# ATA8515 device description
Architecture: AVR8; Family: megaAVR
Registers are 8-bit, access not given, no defined reset value unless marked. A register's access mark holds for its fields unless they carry their own. Offsets are from the block's base; [hi:lo] are bit positions; {n}, {i} and the like mark numbered series.

## FUSE
Instances: FUSE 0 in fuses
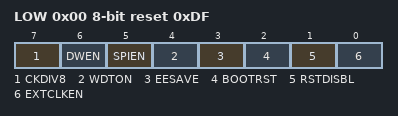
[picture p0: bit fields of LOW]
0x00 LOW reset 0xDF
  [7] CKDIV8 — Divide clock by 8 internally
  [6] DWEN — Debug Wire enable
  [5] SPIEN — Serial program downloading (SPI) enabled
  [4] WDTON — Watch-dog Timer always on
  [3] EESAVE — Preserve EEPROM memory through the Chip Erase cycle
  [2] BOOTRST — Select interrupt vector location
  [1] RSTDISBL — Disable external Reset
  [0] EXTCLKEN — External Clock enable

## LOCKBIT
Instances: LOCKBIT 0 in lockbits
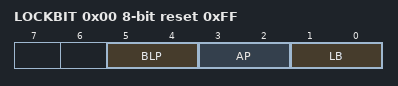
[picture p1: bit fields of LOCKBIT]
0x00 LOCKBIT reset 0xFF
  [5:4] BLP — Boot Loader Protection
    0=LPM_AND_SPM_PROHIBITED_IN_BOOT_LOADER_SECTION; 16=LPM_PROHIBITED_IN_BOOT_LOADER_SECTION; 32=SPM_PROHIBITED_IN_BOOT_LOADER_SECTION; 48=NO_LOCK_ON_SPM_AND_LPM_IN_BOOT_LOADER_SECTION
  [3:2] AP — Application Protection
    0=LPM_AND_SPM_PROHIBITED_IN_APPLICATION_SECTION; 4=LPM_PROHIBITED_IN_APPLICATION_SECTION; 8=SPM_PROHIBITED_IN_APPLICATION_SECTION; 12=NO_LOCK_ON_SPM_AND_LPM_IN_APPLICATION_SECTION
  [1:0] LB — Memory Lock
    0=PROG_VER_DISABLED (Further programming and verification disabled); 2=PROG_DISABLED (Further programming disabled); 3=NO_LOCK (No memory lock features enabled)

## CHFLT
Instances: CHFLT 0x00
0xA9 CHCR — Channel Filter Configuration Register
  [3:0] BWM — Bandwidth Mode
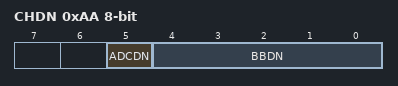
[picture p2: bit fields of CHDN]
0xAA CHDN — Channel Filter Down Sampling Register
  [5] ADCDN — ADC Down Sampling Configuration
  [4:0] BBDN — Baseband Filter Down Sampling Ratio

## CLK
Instances: CLK 0x00
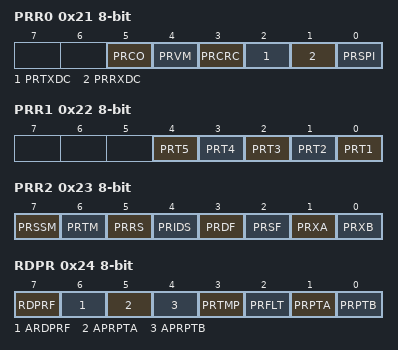
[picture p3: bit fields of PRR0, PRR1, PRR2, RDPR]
0x21 PRR0 — Power Reduction Register 0
  [5] PRCO — Power Reduction Clock Output
  [4] PRVM — Power Reduction Voltage Monitor
  [3] PRCRC — Power Reduction CRC
  [2] PRTXDC — Power Reduction Transmit DSP Control
  [1] PRRXDC — Power Reduction Receive DSP Control
  [0] PRSPI — Power Reduction Serial Peripheral Interface
0x22 PRR1 — Power Reduction Register 1
  [n-1] PRT{n} (n=1..5) — Power Reduction Timer {n}
0x23 PRR2 — Power Reduction Register 2
  [7] PRSSM — Power Reduction Sequencer State Machine
  [6] PRTM — Power Reduction Tx Modulator
  [5] PRRS — Power Reduction RSSI Buffer
  [4] PRIDS — Power Reduction ID Scan
  [3] PRDF — Power Reduction Data FIFO
  [2] PRSF — Power Reduction Preamble/RSSI FIFO
  [1] PRXA — Power Reduction Rx Buffer A
  [0] PRXB — Power Reduction Rx Buffer B
0x24 RDPR — Rx DSP power reduction register
  [7] RDPRF — Rx DSP power reduction register(RDPR) busy flag
  [6] ARDPRF — Automatic Rx DSP Power Reduction Flag
  [5] APRPTA — Automatic Power Reduction of Path A
  [4] APRPTB — Automatic Power Reduction of Path B
  [3] PRTMP — Power reduction register for temperature measurement
  [2] PRFLT — Power reduction register for the digital channel filter
  [1] PRPTA — Power reduction register for the demodulator and receiving path B
  [0] PRPTB — Power reduction register for the demodulator and receiving path A
0xC3 CLKOD — Clock output divider settings Register
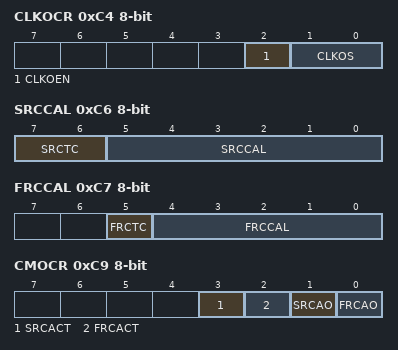
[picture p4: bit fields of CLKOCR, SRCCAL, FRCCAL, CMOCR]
0xC4 CLKOCR — Clock output control Register
  [2] CLKOEN — Clock output driver enable
  [1:0] CLKOS — Clock output source
0xC5 XFUSE
0xC6 SRCCAL — Slow RC oscillator calibration Register
  [7:6] SRCTC — Slow RC oscillator temperature compensation
  [5:0] SRCCAL — Slow RC oscillator calibration
0xC7 FRCCAL — Fast RC oscillator calibration Register
  [5] FRCTC — Fast RC oscillator temperature compensation
  [4:0] FRCCAL — Fast RC oscillator calibration
0xC8 CMSR — Clock management status Register
  [0] ECF — External clock fail
0xC9 CMOCR — Clock management override control register
  [3] SRCACT — SRC Active
  [2] FRCACT — FRC Active
  [1] SRCAO — SRC Always On
  [0] FRCAO — FRC Always On

## CPU
Instances: CPU 0x00
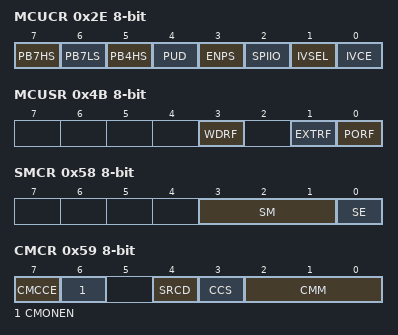
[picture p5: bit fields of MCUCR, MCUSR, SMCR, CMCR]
0x2E MCUCR — MCU Control Register
  [7] PB7HS — Port B7 High Side Driver enable
  [6] PB7LS — Port B7 Low Side Driver enable
  [5] PB4HS — Port B4 High Side Driver enable
  [4] PUD — Pull-up Resistors Disable
  [3] ENPS — Enable Port Settings
  [2] SPIIO — SPI Interrupt Only
  [1] IVSEL — Interrupt Vector Select
  [0] IVCE — Interrupt Vector Change Enable
0x4B MCUSR — MCU Status Register
  [3] WDRF — Watchdog Reset Flag
  [1] EXTRF — External Reset Flag
  [0] PORF — Power-on Reset flag
0x51 DWDR — debugWire communication Register
0x58 SMCR — Sleep mode control Register
  [3:1] SM — Sleep Mode Select
    0=IDLE; 1=EPSAVE (Extended power-save); 2=PDOWN (Power Down); 3=PSAVE (Power Save)
  [0] SE — Sleep Enable
0x59 CMCR — Clock Management Control Register
  [7] CMCCE — Clock management control change enable
  [6] CMONEN — Clock monitor enable
  [4] SRCD — Slow RC oscillator disable
  [3] CCS — Core Clock Select
  [2:0] CMM — Clock Management Mode
0x5A CMIMR — Clock Interrupt Mask Register
  [0] ECIE — External clock interrupt enable
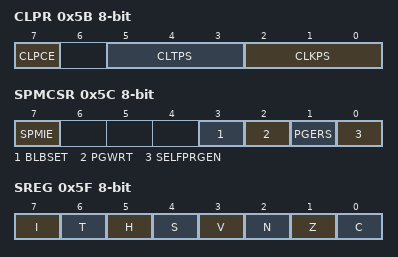
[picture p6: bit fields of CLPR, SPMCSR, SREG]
0x5B CLPR — Clock Prescaler Register
  [7] CLPCE — Clock Prescaler Change Enable
  [5:3] CLTPS — Timer Clock Prescaler Select
    0=DISABLED; 1=1; 2=2; 3=4; 4=8; 5=16; 6=32; 7=64
  [2:0] CLKPS — Clock Prescaler Select
    0=1; 1=2; 2=4; 3=8; 4=16; 5=32; 6=64; 7=128
0x5C SPMCSR — Store Program Memory Control and Status Register
  [7] SPMIE — SPM Interrupt Enable
  [3] BLBSET — Boot Lock Bit Set
  [2] PGWRT — Page Write
  [1] PGERS — Page Erase
  [0] SELFPRGEN — Self Programming Enable
0x5D SP 16-bit bits used 10:0 — Stack Pointer
0x5F SREG — Status Register
  [7] I — Global Interrupt Enable
  [6] T — Bit Copy Storage
  [5] H — Half Carry Flag
  [4] S — Sign Bit
  [3] V — Two's Complement Overflow Flag
  [2] N — Negative Flag
  [1] Z — Zero Flag
  [0] C — Carry Flag
